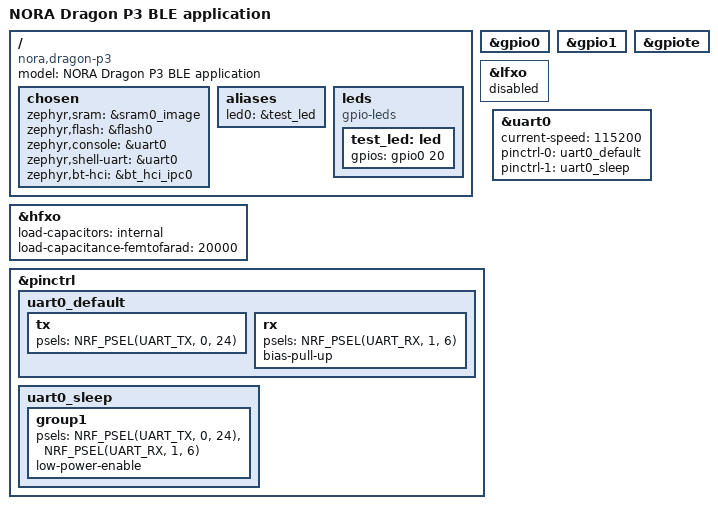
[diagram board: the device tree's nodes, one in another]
/dts-v1/;
#include <nordic/nrf5340_cpuapp_qkaa.dtsi>
#include <nordic/nrf5340_sram_partition.dtsi>
#include <nordic/nrf5340_shared_sram_partition.dtsi>
#include <zephyr/dt-bindings/gpio/gpio.h>
#include <zephyr/dt-bindings/pinctrl/nrf-pinctrl.h>

/ {
    model = "NORA Dragon P3 BLE application";
    compatible = "nora,dragon-p3";
    chosen {
        zephyr,sram = &sram0_image;
        zephyr,flash = &flash0;
        zephyr,console = &uart0;
        zephyr,shell-uart = &uart0;
        zephyr,bt-hci = &bt_hci_ipc0;
    };
    aliases { led0 = &test_led; };
    leds {
        compatible = "gpio-leds";
        test_led: led { gpios = <&gpio0 20 GPIO_ACTIVE_HIGH>; };
    };
};

&gpio0 { status = "okay"; };
&gpio1 { status = "okay"; };
&gpiote { status = "okay"; };
&hfxo { load-capacitors = "internal"; load-capacitance-femtofarad = <20000>; };
&lfxo { status = "disabled"; };

&pinctrl {
    uart0_default: uart0_default {
        tx { psels = <NRF_PSEL(UART_TX, 0, 24)>; };
        rx { psels = <NRF_PSEL(UART_RX, 1, 6)>; bias-pull-up; };
    };
    uart0_sleep: uart0_sleep {
        group1 {
            psels = <NRF_PSEL(UART_TX, 0, 24)>, <NRF_PSEL(UART_RX, 1, 6)>;
            low-power-enable;
        };
    };
};
&uart0 {
    status = "okay";
    current-speed = <115200>;
    pinctrl-0 = <&uart0_default>;
    pinctrl-1 = <&uart0_sleep>;
    pinctrl-names = "default", "sleep";
};
